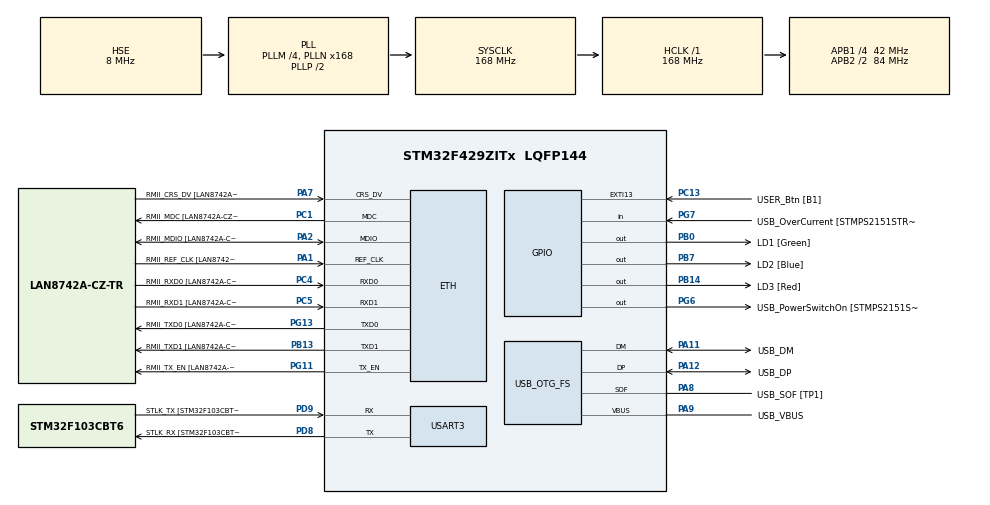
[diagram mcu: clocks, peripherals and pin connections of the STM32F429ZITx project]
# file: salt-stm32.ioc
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ETH.MediaInterface=HAL_ETH_RMII_MODE
ETH.PHY_Name=LAN8742A_PHY_ADDRESS
ETH.PHY_Value=0
ETH.PhyAddress=0
FREERTOS.Tasks01=defaultTask,24,128,StartDefaultTask,Default,NULL,Dynamic,NULL,NULL
Mcu.Family=STM32F4
Mcu.Name=STM32F429ZITx
Mcu.Package=LQFP144
NVIC.PriorityGroup=NVIC_PRIORITYGROUP_4
PA1.GPIO_Label=RMII_REF_CLK [LAN8742A-CZ-TR_REFCLK0]
PA1.Mode=RMII
PA1.Signal=ETH_REF_CLK
PA10.GPIO_Label=USB_ID
PA10.Signal=USB_OTG_FS_ID
PA11.GPIO_Label=USB_DM
PA11.Mode=Device_Only
PA11.Signal=USB_OTG_FS_DM
PA12.GPIO_Label=USB_DP
PA12.Mode=Device_Only
PA12.Signal=USB_OTG_FS_DP
PA13.GPIO_Label=TMS
PA13.Mode=Serial_Wire
PA13.Signal=SYS_JTMS-SWDIO
PA14.GPIO_Label=TCK
PA14.Mode=Serial_Wire
PA14.Signal=SYS_JTCK-SWCLK
PA2.GPIO_Label=RMII_MDIO [LAN8742A-CZ-TR_MDIO]
PA2.Mode=RMII
PA2.Signal=ETH_MDIO
PA7.GPIO_Label=RMII_CRS_DV [LAN8742A-CZ-TR_CRS_DV]
PA7.Mode=RMII
PA7.Signal=ETH_CRS_DV
PA8.GPIO_Label=USB_SOF [TP1]
PA8.Mode=Activate_SOF_FS
PA8.Signal=USB_OTG_FS_SOF
PA9.GPIO_Label=USB_VBUS
PA9.Mode=Activate_VBUS
PA9.Signal=USB_OTG_FS_VBUS
PB0.GPIO_Label=LD1 [Green]
PB0.Signal=GPIO_Output
PB13.GPIO_Label=RMII_TXD1 [LAN8742A-CZ-TR_TXD1]
PB13.Mode=RMII
PB13.Signal=ETH_TXD1
PB14.GPIO_Label=LD3 [Red]
PB14.Signal=GPIO_Output
PB7.GPIO_Label=LD2 [Blue]
PB7.Signal=GPIO_Output
PC1.GPIO_Label=RMII_MDC [LAN8742A-CZ-TR_MDC]
PC1.Mode=RMII
PC1.Signal=ETH_MDC
PC13.GPIO_Label=USER_Btn [B1]
PC13.Signal=GPXTI13
PC14/OSC32_IN.Mode=LSE-External-Oscillator
PC14/OSC32_IN.Signal=RCC_OSC32_IN
PC15/OSC32_OUT.Mode=LSE-External-Oscillator
PC15/OSC32_OUT.Signal=RCC_OSC32_OUT
PC4.GPIO_Label=RMII_RXD0 [LAN8742A-CZ-TR_RXD0]
PC4.Mode=RMII
PC4.Signal=ETH_RXD0
PC5.GPIO_Label=RMII_RXD1 [LAN8742A-CZ-TR_RXD1]
PC5.Mode=RMII
PC5.Signal=ETH_RXD1
PD8.GPIO_Label=STLK_RX [STM32F103CBT6_PA3]
PD8.Mode=Asynchronous
PD8.Signal=USART3_TX
PD9.GPIO_Label=STLK_TX [STM32F103CBT6_PA2]
PD9.Mode=Asynchronous
PD9.Signal=USART3_RX
PG11.GPIO_Label=RMII_TX_EN [LAN8742A-CZ-TR_TXEN]
PG11.Mode=RMII
PG11.Signal=ETH_TX_EN
PG13.GPIO_Label=RMII_TXD0 [LAN8742A-CZ-TR_TXD0]
PG13.Mode=RMII
PG13.Signal=ETH_TXD0
PG6.GPIO_Label=USB_PowerSwitchOn [STMPS2151STR_EN]
PG6.Signal=GPIO_Output
PG7.GPIO_Label=USB_OverCurrent [STMPS2151STR_FAULT]
PG7.Signal=GPIO_Input
PH0/OSC_IN.GPIO_Label=MCO [STM32F103CBT6_PA8]
PH0/OSC_IN.Mode=HSE-External-Clock-Source
PH0/OSC_IN.Signal=RCC_OSC_IN
PH1/OSC_OUT.Mode=HSE-External-Clock-Source
PH1/OSC_OUT.Signal=RCC_OSC_OUT
ProjectManager.HeapSize=0x200
ProjectManager.StackSize=0x400
ProjectManager.TargetToolchain=STM32CubeIDE
RCC.48MHZClocksFreq_Value=48000000
RCC.AHBFreq_Value=168000000
RCC.APB1CLKDivider=RCC_HCLK_DIV4
RCC.APB1Freq_Value=42000000
RCC.APB1TimFreq_Value=84000000
RCC.APB2CLKDivider=RCC_HCLK_DIV2
RCC.APB2Freq_Value=84000000
RCC.APB2TimCLKDivider=2
RCC.APB2TimFreq_Value=168000000
RCC.CortexFreq_Value=168000000
RCC.HCLKFreq_Value=168000000
RCC.HSE_VALUE=8000000
RCC.HSI_VALUE=16000000
RCC.PLLM=4
RCC.PLLMUL=RCC_PLL_MUL9
RCC.PLLN=168
RCC.PLLQ=7
RCC.PRESCALERUSB=RCC_USBCLKSOURCE_PLL_DIV1_5
RCC.SYSCLKFreq_VALUE=168000000
RCC.SYSCLKSource=RCC_SYSCLKSOURCE_PLLCLK
RCC.SYSCLKSourceVirtual=RCC_SYSCLKSOURCE_PLLCLK
RCC.USBFreq_Value=48000000
RCC.VCOOutputFreq_Value=336000000
USART3.VirtualMode=VM_ASYNC
USB_OTG_FS.VirtualMode=Device_Only
VP_FREERTOS_VS_CMSIS_V2.Mode=CMSIS_V2
board=NUCLEO-F429ZI

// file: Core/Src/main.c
/* USER CODE BEGIN Header */
/**
  ******************************************************************************
  * @file           : main.c
  * @brief          : Main program body
  ******************************************************************************
  * @attention
  *
  * Copyright (c) 2022 STMicroelectronics.
  * All rights reserved.
  *
  * This software is licensed under terms that can be found in the LICENSE file
  * in the root directory of this software component.
  * If no LICENSE file comes with this software, it is provided AS-IS.
  *
  ******************************************************************************
  */
/* USER CODE END Header */
#include "main.h"
#include "string.h"
#include "cmsis_os.h"

#include "FreeRTOS.h"

//////////////////////////////////////////////////////////////////////////////////////////////////////////////////////
#include "core_mqtt.h"
#include "backoff_algorithm.h"
#include "using_plaintext.h"
#include "logging_stack.h"

/*-----------------------------------------------------------*/
/* Used by the pseudo random number generator. */
static UBaseType_t ulNextRand;

UBaseType_t uxRand( void )
{
    const uint32_t ulMultiplier = 0x015a4e35UL, ulIncrement = 1UL;

    /*
     * Utility function to generate a pseudo random number.
     *
     * !!!NOTE!!!
     * This is not a secure method of generating a random number.  Production
     * devices should use a True Random Number Generator (TRNG).
     */
    ulNextRand = ( ulMultiplier * ulNextRand ) + ulIncrement;
    return( ( int ) ( ulNextRand >> 16UL ) & 0x7fffUL );
}
/*-----------------------------------------------------------*/

/*
 * Demo for showing use of the managed MQTT API.
 *
 * The Example shown below uses this API to create MQTT messages and
 * send them over the connection established using FreeRTOS sockets.
 * The example is single threaded and uses statically allocated memory;
 * it uses QOS0 and therefore does not implement any retransmission
 * mechanism for Publish messages.
 *
 * !!! NOTE !!!
 * This MQTT demo does not authenticate the server nor the client.
 * Hence, this demo should not be used as production ready code.
 *
 * Also see https://www.freertos.org/mqtt/mqtt-agent-demo.html? for an
 * alternative run time model whereby coreMQTT runs in an autonomous
 * background agent task.  Executing the MQTT protocol in an agent task
 * removes the need for the application writer to explicitly manage any MQTT
 * state or call the MQTT_ProcessLoop() API function. Using an agent task
 * also enables multiple application tasks to more easily share a single
 * MQTT connection.
 */

/* Standard includes. */
#include <string.h>
#include <stdio.h>

/* Kernel includes. */
#include "FreeRTOS.h"
#include "task.h"

/* Demo Specific configs. */
#include "demo_config.h"

/* MQTT library includes. */
#include "core_mqtt.h"

/* Exponential backoff retry include. */
#include "backoff_algorithm.h"

/* Transport interface include. */
#include "using_plaintext.h"

/*-----------------------------------------------------------*/

/* Compile time error for undefined configs. */
#ifndef democonfigMQTT_BROKER_ENDPOINT
#error "Define the config democonfigMQTT_BROKER_ENDPOINT by following the instructions in file demo_config.h."
#endif

/*-----------------------------------------------------------*/

/* Default values for configs. */
#ifndef democonfigCLIENT_IDENTIFIER

/**
 * @brief The MQTT client identifier used in this example.  Each client identifier
 * must be unique so edit as required to ensure no two clients connecting to the
 * same broker use the same client identifier.
 *
 * @note Appending __TIME__ to the client id string will reduce the possibility of a
 * client id collision in the broker. Note that the appended time is the compilation
 * time. This client id can cause collision, if more than one instance of the same
 * binary is used at the same time to connect to the broker.
 */
#define democonfigCLIENT_IDENTIFIER    "testClient"__TIME__
#endif

#ifndef democonfigMQTT_BROKER_PORT

/**
 * @brief The port to use for the demo.
 */
#define democonfigMQTT_BROKER_PORT    ( 1883 )
#endif

/*-----------------------------------------------------------*/

/**
 * @brief The maximum number of retries for network operation with server.
 */
#define mqttexampleRETRY_MAX_ATTEMPTS            ( 5U )

/**
 * @brief The maximum back-off delay (in milliseconds) for retrying failed operation
 *  with server.
 */
#define mqttexampleRETRY_MAX_BACKOFF_DELAY_MS    ( 5000U )

/**
 * @brief The base back-off delay (in milliseconds) to use for network operation retry
 * attempts.
 */
#define mqttexampleRETRY_BACKOFF_BASE_MS         ( 500U )

/**
 * @brief Timeout for receiving CONNACK packet in milliseconds.
 */
#define mqttexampleCONNACK_RECV_TIMEOUT_MS           ( 1000U )

/**
 * @brief The topic to subscribe and publish to in the example.
 *
 * The topic name starts with the client identifier to ensure that each demo
 * interacts with a unique topic name.
 */
#define mqttexampleTOPIC                             democonfigCLIENT_IDENTIFIER "/example/topic"

/**
 * @brief The number of topic filters to subscribe.
 */
#define mqttexampleTOPIC_COUNT                       ( 1 )

/**
 * @brief The MQTT message published in this example.
 */
#define mqttexampleMESSAGE                           "Hello World!"

/**
 * @brief Dimensions a file scope buffer currently used to send and receive MQTT data
 * from a socket.
 */
#define mqttexampleSHARED_BUFFER_SIZE                ( 500U )

/**
 * @brief Time to wait between each cycle of the demo implemented by prvMQTTDemoTask().
 */
#define mqttexampleDELAY_BETWEEN_DEMO_ITERATIONS     ( pdMS_TO_TICKS( 5000U ) )

/**
 * @brief Timeout for MQTT_ProcessLoop in milliseconds.
 */
#define mqttexamplePROCESS_LOOP_TIMEOUT_MS           ( 500U )

/**
 * @brief Keep alive time reported to the broker while establishing an MQTT connection.
 *
 * It is the responsibility of the Client to ensure that the interval between
 * Control Packets being sent does not exceed the this Keep Alive value. In the
 * absence of sending any other Control Packets, the Client MUST send a
 * PINGREQ Packet.
 */
#define mqttexampleKEEP_ALIVE_TIMEOUT_SECONDS        ( 60U )

/**
 * @brief Delay between MQTT publishes. Note that the process loop also has a
 * timeout, so the total time between publishes is the sum of the two delays.
 */
#define mqttexampleDELAY_BETWEEN_PUBLISHES           ( pdMS_TO_TICKS( 500U ) )

/**
 * @brief Transport timeout in milliseconds for transport send and receive.
 */
#define mqttexampleTRANSPORT_SEND_RECV_TIMEOUT_MS    ( 200U )

#define MILLISECONDS_PER_SECOND                      ( 1000U )                                        /**< @brief Milliseconds per second. */
#define MILLISECONDS_PER_TICK                        ( MILLISECONDS_PER_SECOND / configTICK_RATE_HZ ) /**< Milliseconds per FreeRTOS tick. */

/*-----------------------------------------------------------*/

/**
 * @brief Each compilation unit that consumes the NetworkContext must define it.
 * It should contain a single pointer to the type of your desired transport.
 * When using multiple transports in the same compilation unit, define this pointer as void *.
 *
 * @note Transport stacks are defined in FreeRTOS-Plus/Source/Application-Protocols/network_transport.
 */
struct NetworkContext
{
    PlaintextTransportParams_t * pParams;
};

/*-----------------------------------------------------------*/

/**
 * @brief The task used to demonstrate the MQTT API.
 *
 * @param[in] pvParameters Parameters as passed at the time of task creation. Not
 * used in this example.
 */
static void prvMQTTDemoTask( void * pvParameters );

/**
 * @brief Connect to MQTT broker with reconnection retries.
 *
 * If connection fails, retry is attempted after a timeout.
 * Timeout value will exponentially increase until maximum
 * timeout value is reached or the number of attempts are exhausted.
 *
 * @param[out] pxNetworkContext The parameter to return the created network context.
 *
 * @return The status of the final connection attempt.
 */
static PlaintextTransportStatus_t prvConnectToServerWithBackoffRetries( NetworkContext_t * pxNetworkContext );

/**
 * @brief Sends an MQTT Connect packet over the already connected TCP socket.
 *
 * @param[in, out] pxMQTTContext MQTT context pointer.
 * @param[in] pxNetworkContext Network context.
 *
 */
static void prvCreateMQTTConnectionWithBroker( MQTTContext_t * pxMQTTContext,
                                               NetworkContext_t * pxNetworkContext );

/**
 * @brief Function to update variable #xTopicFilterContext with status
 * information from Subscribe ACK. Called by the event callback after processing
 * an incoming SUBACK packet.
 *
 * @param[in] Server response to the subscription request.
 */
static void prvUpdateSubAckStatus( MQTTPacketInfo_t * pxPacketInfo );

/**
 * @brief Subscribes to the topic as specified in mqttexampleTOPIC at the top of
 * this file. In the case of a Subscribe ACK failure, then subscription is
 * retried using an exponential backoff strategy with jitter.
 *
 * @param[in] pxMQTTContext MQTT context pointer.
 */
static void prvMQTTSubscribeWithBackoffRetries( MQTTContext_t * pxMQTTContext );

/**
 * @brief Publishes a message mqttexampleMESSAGE on mqttexampleTOPIC topic.
 *
 * @param[in] pxMQTTContext MQTT context pointer.
 */
static void prvMQTTPublishToTopic( MQTTContext_t * pxMQTTContext );

/**
 * @brief Unsubscribes from the previously subscribed topic as specified
 * in mqttexampleTOPIC.
 *
 * @param[in] pxMQTTContext MQTT context pointer.
 */
static void prvMQTTUnsubscribeFromTopic( MQTTContext_t * pxMQTTContext );

/**
 * @brief The timer query function provided to the MQTT context.
 *
 * @return Time in milliseconds.
 */
static uint32_t prvGetTimeMs( void );

/**
 * @brief Process a response or ack to an MQTT request (PING, SUBSCRIBE
 * or UNSUBSCRIBE). This function processes PINGRESP, SUBACK, and UNSUBACK.
 *
 * @param[in] pxIncomingPacket is a pointer to structure containing deserialized
 * MQTT response.
 * @param[in] usPacketId is the packet identifier from the ack received.
 */
static void prvMQTTProcessResponse( MQTTPacketInfo_t * pxIncomingPacket,
                                    uint16_t usPacketId );

/**
 * @brief Process incoming Publish message.
 *
 * @param[in] pxPublishInfo is a pointer to structure containing deserialized
 * Publish message.
 */
static void prvMQTTProcessIncomingPublish( MQTTPublishInfo_t * pxPublishInfo );

/**
 * @brief The application callback function for getting the incoming publish
 * and incoming acks reported from the MQTT library.
 *
 * @param[in] pxMQTTContext MQTT context pointer.
 * @param[in] pxPacketInfo Packet Info pointer for the incoming packet.
 * @param[in] pxDeserializedInfo Deserialized information from the incoming packet.
 */
static void prvEventCallback( MQTTContext_t * pxMQTTContext,
                              MQTTPacketInfo_t * pxPacketInfo,
                              MQTTDeserializedInfo_t * pxDeserializedInfo );

/*-----------------------------------------------------------*/

/**
 * @brief Static buffer used to hold MQTT messages being sent and received.
 */
static uint8_t ucSharedBuffer[ mqttexampleSHARED_BUFFER_SIZE ];

/**
 * @brief Global entry time into the application to use as a reference timestamp
 * in the #prvGetTimeMs function. #prvGetTimeMs will always return the difference
 * between the current time and the global entry time. This will reduce the chances
 * of overflow for the 32 bit unsigned integer used for holding the timestamp.
 */
static uint32_t ulGlobalEntryTimeMs;

/**
 * @brief Packet Identifier generated when Subscribe request was sent to the broker;
 * it is used to match received Subscribe ACK to the transmitted ACK.
 */
static uint16_t usSubscribePacketIdentifier;

/**
 * @brief Packet Identifier generated when Unsubscribe request was sent to the broker;
 * it is used to match received Unsubscribe response to the transmitted unsubscribe
 * request.
 */
static uint16_t usUnsubscribePacketIdentifier;

/**
 * @brief A pair containing a topic filter and its SUBACK status.
 */
typedef struct topicFilterContext
{
    const char * pcTopicFilter;
    MQTTSubAckStatus_t xSubAckStatus;
} topicFilterContext_t;

/**
 * @brief An array containing the context of a SUBACK; the SUBACK status
 * of a filter is updated when the event callback processes a SUBACK.
 */
static topicFilterContext_t xTopicFilterContext[ mqttexampleTOPIC_COUNT ] =
        {
                { mqttexampleTOPIC, MQTTSubAckFailure }
        };

/**
 * @brief Static buffer used to hold MQTT messages being sent and received.
 */
static MQTTFixedBuffer_t xBuffer =
        {
                .pBuffer = ucSharedBuffer,
                .size    = mqttexampleSHARED_BUFFER_SIZE
        };

/*-----------------------------------------------------------*/

/**
 * @brief Create the task that demonstrates the MQTT API over a plaintext TCP
 * connection.
 */
void vStartSimpleMQTTDemo( void )
{
    /* This example uses a single application task, which in turn is used to
     * connect, subscribe, publish, unsubscribe and disconnect from the MQTT
     * broker.
     *
     * Also see https://www.freertos.org/mqtt/mqtt-agent-demo.html? for an
     * alternative run time model whereby coreMQTT runs in an autonomous
     * background agent task.  Executing the MQTT protocol in an agent task
     * removes the need for the application writer to explicitly manage any MQTT
     * state or call the MQTT_ProcessLoop() API function. Using an agent task
     * also enables multiple application tasks to more easily share a single
     * MQTT connection.*/
    xTaskCreate( prvMQTTDemoTask,          /* Function that implements the task. */
                 "DemoTask",               /* Text name for the task - only used for debugging. */
                 democonfigDEMO_STACKSIZE, /* Size of stack (in words, not bytes) to allocate for the task. */
                 NULL,                     /* Task parameter - not used in this case. */
                 tskIDLE_PRIORITY,         /* Task priority, must be between 0 and configMAX_PRIORITIES - 1. */
                 NULL );                   /* Used to pass out a handle to the created task - not used in this case. */
}
/*-----------------------------------------------------------*/

static void prvMQTTDemoTask( void * pvParameters )
{
    uint32_t ulPublishCount = 0U, ulTopicCount = 0U;
    const uint32_t ulMaxPublishCount = 5UL;
    NetworkContext_t xNetworkContext = { 0 };
    PlaintextTransportParams_t xPlaintextTransportParams = { 0 };
    MQTTContext_t xMQTTContext;
    MQTTStatus_t xMQTTStatus;
    PlaintextTransportStatus_t xNetworkStatus;

    /* Remove compiler warnings about unused parameters. */
    ( void ) pvParameters;

    /* Set the pParams member of the network context with desired transport. */
    xNetworkContext.pParams = &xPlaintextTransportParams;

    ulGlobalEntryTimeMs = prvGetTimeMs();

    for( ; ; )
    {
        /****************************** Connect. ******************************/

        /* Attempt to connect to the MQTT broker. If connection fails, retry after
         * a timeout. The timeout value will exponentially increase until the
         * maximum number of attempts are reached or the maximum timeout value is
         * reached. The function below returns a failure status if the TCP connection
         * cannot be established to the broker after the configured number of attempts. */
        xNetworkStatus = prvConnectToServerWithBackoffRetries( &xNetworkContext );
        configASSERT( xNetworkStatus == PLAINTEXT_TRANSPORT_SUCCESS );

        /* Sends an MQTT Connect packet over the already connected TCP socket,
         * and waits for a connection acknowledgment (CONNACK) packet. */
        LogInfo( ( "Creating an MQTT connection to %s.", democonfigMQTT_BROKER_ENDPOINT ) );
        prvCreateMQTTConnectionWithBroker( &xMQTTContext, &xNetworkContext );

        /**************************** Subscribe. ******************************/

        /* If server rejected the subscription request, attempt to resubscribe to
         * the topic. Attempts are made according to the exponential backoff retry
         * strategy declared in backoff_algorithm.h. */
        prvMQTTSubscribeWithBackoffRetries( &xMQTTContext );

        /******************* Publish and Keep Alive Loop. *********************/
        /* Publish messages with QoS0, then send and process Keep Alive messages. */
        for( ulPublishCount = 0; ulPublishCount < ulMaxPublishCount; ulPublishCount++ )
        {
            LogInfo( ( "Publish to the MQTT topic %s.", mqttexampleTOPIC ) );
            prvMQTTPublishToTopic( &xMQTTContext );

            /* Process the incoming publish echo. Since the application subscribed
             * to the same topic, the broker will send the same publish message
             * back to the application. */
            LogInfo( ( "Attempt to receive publish message from broker." ) );
            //xMQTTStatus = MQTT_ProcessLoop( &xMQTTContext, mqttexamplePROCESS_LOOP_TIMEOUT_MS );
            xMQTTStatus = MQTT_ProcessLoop( &xMQTTContext );
            configASSERT( xMQTTStatus == MQTTSuccess );

            /* Leave the connection idle for some time. */
            LogInfo( ( "Keeping Connection Idle...\r\n" ) );
            vTaskDelay( mqttexampleDELAY_BETWEEN_PUBLISHES );
        }

        /******************** Unsubscribe from the topic. *********************/
        LogInfo( ( "Unsubscribe from the MQTT topic %s.", mqttexampleTOPIC ) );
        prvMQTTUnsubscribeFromTopic( &xMQTTContext );

        /* Process the incoming packet from the broker. */
        //xMQTTStatus = MQTT_ProcessLoop( &xMQTTContext, mqttexamplePROCESS_LOOP_TIMEOUT_MS );
        xMQTTStatus = MQTT_ProcessLoop( &xMQTTContext );
        configASSERT( xMQTTStatus == MQTTSuccess );

        /**************************** Disconnect. *****************************/

        /* Send an MQTT Disconnect packet over the connected TCP socket.
         * There is no corresponding response for a disconnect packet. After
         * sending the disconnect, the client must close the network connection. */
        LogInfo( ( "Disconnecting the MQTT connection with %s.",
                democonfigMQTT_BROKER_ENDPOINT ) );
        xMQTTStatus = MQTT_Disconnect( &xMQTTContext );
        configASSERT( xMQTTStatus == MQTTSuccess );

        /* Close the network connection. */
        xNetworkStatus = Plaintext_FreeRTOS_Disconnect( &xNetworkContext );
        configASSERT( xNetworkStatus == PLAINTEXT_TRANSPORT_SUCCESS );

        /* Reset SUBACK status for each topic filter after completion of
         * subscription request cycle. */
        for( ulTopicCount = 0; ulTopicCount < mqttexampleTOPIC_COUNT; ulTopicCount++ )
        {
            xTopicFilterContext[ ulTopicCount ].xSubAckStatus = MQTTSubAckFailure;
        }

        /* Wait for some time between two iterations to ensure that we do not
         * bombard the MQTT broker. */
        LogInfo( ( "prvMQTTDemoTask() completed an iteration successfully. "
                   "Total free heap is %u.", xPortGetFreeHeapSize() ) );
        LogInfo( ( "Demo completed successfully." ) );
        LogInfo( ( "Short delay before starting the next iteration.... \r\n" ) );
        vTaskDelay( mqttexampleDELAY_BETWEEN_DEMO_ITERATIONS );
    }
}
/*-----------------------------------------------------------*/

static PlaintextTransportStatus_t prvConnectToServerWithBackoffRetries( NetworkContext_t * pxNetworkContext )
{
    PlaintextTransportStatus_t xNetworkStatus;
    BackoffAlgorithmStatus_t xBackoffAlgStatus = BackoffAlgorithmSuccess;
    BackoffAlgorithmContext_t xReconnectParams;
    uint16_t usNextRetryBackOff = 0U;

    /* Initialize reconnect attempts and interval.*/
    BackoffAlgorithm_InitializeParams( &xReconnectParams,
                                       mqttexampleRETRY_BACKOFF_BASE_MS,
                                       mqttexampleRETRY_MAX_BACKOFF_DELAY_MS,
                                       mqttexampleRETRY_MAX_ATTEMPTS );

    /* Attempt to connect to MQTT broker. If connection fails, retry after
     * a timeout. Timeout value will exponentially increase till maximum
     * attempts are reached.
     */
    do
    {
        /* Establish a TCP connection with the MQTT broker. This example connects to
         * the MQTT broker as specified in democonfigMQTT_BROKER_ENDPOINT and
         * democonfigMQTT_BROKER_PORT at the top of this file. */
        LogInfo( ( "Create a TCP connection to %s:%d.",
                democonfigMQTT_BROKER_ENDPOINT,
                democonfigMQTT_BROKER_PORT ) );
        xNetworkStatus = Plaintext_FreeRTOS_Connect( pxNetworkContext,
                                                     democonfigMQTT_BROKER_ENDPOINT,
                                                     democonfigMQTT_BROKER_PORT,
                                                     mqttexampleTRANSPORT_SEND_RECV_TIMEOUT_MS,
                                                     mqttexampleTRANSPORT_SEND_RECV_TIMEOUT_MS );

        if( xNetworkStatus != PLAINTEXT_TRANSPORT_SUCCESS )
        {
            /* Generate a random number and calculate backoff value (in milliseconds) for
             * the next connection retry.
             * Note: It is recommended to seed the random number generator with a device-specific
             * entropy source so that possibility of multiple devices retrying failed network operations
             * at similar intervals can be avoided. */
            xBackoffAlgStatus = BackoffAlgorithm_GetNextBackoff( &xReconnectParams, uxRand(), &usNextRetryBackOff );

            if( xBackoffAlgStatus == BackoffAlgorithmRetriesExhausted )
            {
                FreeRTOS_printf( ( "Connection to the broker failed, all attempts exhausted." ) );
            }
            else if( xBackoffAlgStatus == BackoffAlgorithmSuccess )
            {
                LogWarn( ( "Connection to the broker failed. "
                           "Retrying connection with backoff and jitter." ) );
                vTaskDelay( pdMS_TO_TICKS( usNextRetryBackOff ) );
            }
        }
    } while( ( xNetworkStatus != PLAINTEXT_TRANSPORT_SUCCESS ) && ( xBackoffAlgStatus == BackoffAlgorithmSuccess ) );

    return xNetworkStatus;
}
/*-----------------------------------------------------------*/

static void prvCreateMQTTConnectionWithBroker( MQTTContext_t * pxMQTTContext,
                                               NetworkContext_t * pxNetworkContext )
{
    MQTTStatus_t xResult;
    MQTTConnectInfo_t xConnectInfo;
    bool xSessionPresent;
    TransportInterface_t xTransport;

    /***
     * For readability, error handling in this function is restricted to the use of
     * asserts().
     ***/

    /* Fill in Transport Interface send and receive function pointers. */
    xTransport.pNetworkContext = pxNetworkContext;
    xTransport.send = Plaintext_FreeRTOS_send;
    xTransport.recv = Plaintext_FreeRTOS_recv;

    /* Initialize MQTT library. */
    xResult = MQTT_Init( pxMQTTContext, &xTransport, prvGetTimeMs, prvEventCallback, &xBuffer );
    configASSERT( xResult == MQTTSuccess );

    /* Many fields not used in this demo so start with everything at 0. */
    ( void ) memset( ( void * ) &xConnectInfo, 0x00, sizeof( xConnectInfo ) );

    /* Start with a clean session i.e. direct the MQTT broker to discard any
     * previous session data. Also, establishing a connection with clean session
     * will ensure that the broker does not store any data when this client
     * gets disconnected. */
    xConnectInfo.cleanSession = true;

    /* The client identifier is used to uniquely identify this MQTT client to
     * the MQTT broker. In a production device the identifier can be something
     * unique, such as a device serial number. */
    xConnectInfo.pClientIdentifier = democonfigCLIENT_IDENTIFIER;
    xConnectInfo.clientIdentifierLength = ( uint16_t ) strlen( democonfigCLIENT_IDENTIFIER );

    /* Set MQTT keep-alive period. It is the responsibility of the application to ensure
     * that the interval between Control Packets being sent does not exceed the Keep Alive value.
     * In the absence of sending any other Control Packets, the Client MUST send a PINGREQ Packet. */
    xConnectInfo.keepAliveSeconds = mqttexampleKEEP_ALIVE_TIMEOUT_SECONDS;

    /* Send MQTT CONNECT packet to broker. LWT is not used in this demo, so it
     * is passed as NULL. */
    xResult = MQTT_Connect( pxMQTTContext,
                            &xConnectInfo,
                            NULL,
                            mqttexampleCONNACK_RECV_TIMEOUT_MS,
                            &xSessionPresent );
    configASSERT( xResult == MQTTSuccess );
}
/*-----------------------------------------------------------*/

static void prvUpdateSubAckStatus( MQTTPacketInfo_t * pxPacketInfo )
{
    MQTTStatus_t xResult = MQTTSuccess;
    uint8_t * pucPayload = NULL;
    size_t ulSize = 0;
    uint32_t ulTopicCount = 0U;

    xResult = MQTT_GetSubAckStatusCodes( pxPacketInfo, &pucPayload, &ulSize );

    /* MQTT_GetSubAckStatusCodes always returns success if called with packet info
     * from the event callback and non-NULL parameters. */
    configASSERT( xResult == MQTTSuccess );

    for( ulTopicCount = 0; ulTopicCount < ulSize; ulTopicCount++ )
    {
        xTopicFilterContext[ ulTopicCount ].xSubAckStatus = pucPayload[ ulTopicCount ];
    }
}
/*-----------------------------------------------------------*/

static void prvMQTTSubscribeWithBackoffRetries( MQTTContext_t * pxMQTTContext )
{
    MQTTStatus_t xResult = MQTTSuccess;
    BackoffAlgorithmStatus_t xBackoffAlgStatus = BackoffAlgorithmSuccess;
    BackoffAlgorithmContext_t xRetryParams;
    uint16_t usNextRetryBackOff = 0U;
    MQTTSubscribeInfo_t xMQTTSubscription[ mqttexampleTOPIC_COUNT ];
    bool xFailedSubscribeToTopic = false;
    uint32_t ulTopicCount = 0U;

    /* Some fields not used by this demo so start with everything at 0. */
    ( void ) memset( ( void * ) &xMQTTSubscription, 0x00, sizeof( xMQTTSubscription ) );

    /* Get a unique packet id. */
    usSubscribePacketIdentifier = MQTT_GetPacketId( pxMQTTContext );

    /* Subscribe to the mqttexampleTOPIC topic filter. This example subscribes to
     * only one topic and uses QoS0. */
    xMQTTSubscription[ 0 ].qos = MQTTQoS0;
    xMQTTSubscription[ 0 ].pTopicFilter = mqttexampleTOPIC;
    xMQTTSubscription[ 0 ].topicFilterLength = ( uint16_t ) strlen( mqttexampleTOPIC );

    /* Initialize context for backoff retry attempts if SUBSCRIBE request fails. */
    BackoffAlgorithm_InitializeParams( &xRetryParams,
                                       mqttexampleRETRY_BACKOFF_BASE_MS,
                                       mqttexampleRETRY_MAX_BACKOFF_DELAY_MS,
                                       mqttexampleRETRY_MAX_ATTEMPTS );

    do
    {
        /* The client is now connected to the broker. Subscribe to the topic
         * as specified in mqttexampleTOPIC at the top of this file by sending a
         * subscribe packet then waiting for a subscribe acknowledgment (SUBACK).
         * This client will then publish to the same topic it subscribed to, so it
         * will expect all the messages it sends to the broker to be sent back to it
         * from the broker. This demo uses QOS0 in Subscribe, therefore, the Publish
         * messages received from the broker will have QOS0. */
        LogInfo( ( "Attempt to subscribe to the MQTT topic %s.", mqttexampleTOPIC ) );
        xResult = MQTT_Subscribe( pxMQTTContext,
                                  xMQTTSubscription,
                                  sizeof( xMQTTSubscription ) / sizeof( MQTTSubscribeInfo_t ),
                                  usSubscribePacketIdentifier );
        configASSERT( xResult == MQTTSuccess );

        LogInfo( ( "SUBSCRIBE sent for topic %s to broker.\n\n", mqttexampleTOPIC ) );

        /* Process incoming packet from the broker. After sending the subscribe, the
         * client may receive a publish before it receives a subscribe ack. Therefore,
         * call generic incoming packet processing function. Since this demo is
         * subscribing to the topic to which no one is publishing, probability of
         * receiving Publish message before subscribe ack is zero; but application
         * must be ready to receive any packet.  This demo uses the generic packet
         * processing function everywhere to highlight this fact. */
        //xResult = MQTT_ProcessLoop( pxMQTTContext, mqttexamplePROCESS_LOOP_TIMEOUT_MS );
        xResult = MQTT_ProcessLoop( pxMQTTContext );
        configASSERT( xResult == MQTTSuccess );

        /* Reset flag before checking suback responses. */
        xFailedSubscribeToTopic = false;

        /* Check if recent subscription request has been rejected. #xTopicFilterContext is updated
         * in the event callback to reflect the status of the SUBACK sent by the broker. It represents
         * either the QoS level granted by the server upon subscription, or acknowledgement of
         * server rejection of the subscription request. */
        for( ulTopicCount = 0; ulTopicCount < mqttexampleTOPIC_COUNT; ulTopicCount++ )
        {
            if( xTopicFilterContext[ ulTopicCount ].xSubAckStatus == MQTTSubAckFailure )
            {
                xFailedSubscribeToTopic = true;

                /* Generate a random number and calculate backoff value (in milliseconds) for
                 * the next connection retry.
                 * Note: It is recommended to seed the random number generator with a device-specific
                 * entropy source so that possibility of multiple devices retrying failed network operations
                 * at similar intervals can be avoided. */
                xBackoffAlgStatus = BackoffAlgorithm_GetNextBackoff( &xRetryParams, uxRand(), &usNextRetryBackOff );

                if( xBackoffAlgStatus == BackoffAlgorithmRetriesExhausted )
                {
                    FreeRTOS_printf( ( "Server rejected subscription request. All retry attempts have exhausted. Topic=%s",
                            xTopicFilterContext[ ulTopicCount ].pcTopicFilter ) );
                }
                else if( xBackoffAlgStatus == BackoffAlgorithmSuccess )
                {
                    LogWarn( ( "Server rejected subscription request. Attempting to re-subscribe to topic %s.",
                            xTopicFilterContext[ ulTopicCount ].pcTopicFilter ) );
                    /* Backoff before the next re-subscribe attempt. */
                    vTaskDelay( pdMS_TO_TICKS( usNextRetryBackOff ) );
                }

                break;
            }
        }

        configASSERT( xBackoffAlgStatus != BackoffAlgorithmRetriesExhausted );
    } while( ( xFailedSubscribeToTopic == true ) && ( xBackoffAlgStatus == BackoffAlgorithmSuccess ) );
}
/*-----------------------------------------------------------*/

static void prvMQTTPublishToTopic( MQTTContext_t * pxMQTTContext )
{
    MQTTStatus_t xResult;
    MQTTPublishInfo_t xMQTTPublishInfo;

    /***
     * For readability, error handling in this function is restricted to the use of
     * asserts().
     ***/

    /* Some fields are not used by this demo so start with everything at 0. */
    ( void ) memset( ( void * ) &xMQTTPublishInfo, 0x00, sizeof( xMQTTPublishInfo ) );

    /* This demo uses QoS0. */
    xMQTTPublishInfo.qos = MQTTQoS0;
    xMQTTPublishInfo.retain = false;
    xMQTTPublishInfo.pTopicName = mqttexampleTOPIC;
    xMQTTPublishInfo.topicNameLength = ( uint16_t ) strlen( mqttexampleTOPIC );
    xMQTTPublishInfo.pPayload = mqttexampleMESSAGE;
    xMQTTPublishInfo.payloadLength = strlen( mqttexampleMESSAGE );

    /* Send PUBLISH packet. Packet ID is not used for a QoS0 publish. */
    xResult = MQTT_Publish( pxMQTTContext, &xMQTTPublishInfo, 0U );

    configASSERT( xResult == MQTTSuccess );
}
/*-----------------------------------------------------------*/

static void prvMQTTUnsubscribeFromTopic( MQTTContext_t * pxMQTTContext )
{
    MQTTStatus_t xResult;
    MQTTSubscribeInfo_t xMQTTSubscription[ mqttexampleTOPIC_COUNT ];

    /* Some fields not used by this demo so start with everything at 0. */
    ( void ) memset( ( void * ) &xMQTTSubscription, 0x00, sizeof( xMQTTSubscription ) );

    /* Get a unique packet id. */
    usSubscribePacketIdentifier = MQTT_GetPacketId( pxMQTTContext );

    /* Subscribe to the mqttexampleTOPIC topic filter. This example subscribes to
     * only one topic and uses QoS0. */
    xMQTTSubscription[ 0 ].qos = MQTTQoS0;
    xMQTTSubscription[ 0 ].pTopicFilter = mqttexampleTOPIC;
    xMQTTSubscription[ 0 ].topicFilterLength = ( uint16_t ) strlen( mqttexampleTOPIC );

    /* Get next unique packet identifier. */
    usUnsubscribePacketIdentifier = MQTT_GetPacketId( pxMQTTContext );

    /* Send UNSUBSCRIBE packet. */
    xResult = MQTT_Unsubscribe( pxMQTTContext,
                                xMQTTSubscription,
                                sizeof( xMQTTSubscription ) / sizeof( MQTTSubscribeInfo_t ),
                                usUnsubscribePacketIdentifier );

    configASSERT( xResult == MQTTSuccess );
}
/*-----------------------------------------------------------*/

static void prvMQTTProcessResponse( MQTTPacketInfo_t * pxIncomingPacket,
                                    uint16_t usPacketId )
{
    uint32_t ulTopicCount = 0U;

    switch( pxIncomingPacket->type )
    {
        case MQTT_PACKET_TYPE_SUBACK:

            /* A SUBACK from the broker, containing the server response to our subscription request, has been received.
             * It contains the status code indicating server approval/rejection for the subscription to the single topic
             * requested. The SUBACK will be parsed to obtain the status code, and this status code will be stored in global
             * variable #xTopicFilterContext. */
            prvUpdateSubAckStatus( pxIncomingPacket );

            for( ulTopicCount = 0; ulTopicCount < mqttexampleTOPIC_COUNT; ulTopicCount++ )
            {
                if( xTopicFilterContext[ ulTopicCount ].xSubAckStatus != MQTTSubAckFailure )
                {
                    LogInfo( ( "Subscribed to the topic %s with maximum QoS %u.",
                            xTopicFilterContext[ ulTopicCount ].pcTopicFilter,
                            xTopicFilterContext[ ulTopicCount ].xSubAckStatus ) );
                }
            }

            /* Make sure ACK packet identifier matches with Request packet identifier. */
            configASSERT( usSubscribePacketIdentifier == usPacketId );
            break;

        case MQTT_PACKET_TYPE_UNSUBACK:
        LogInfo( ( "Unsubscribed from the topic %s.", mqttexampleTOPIC ) );
            /* Make sure ACK packet identifier matches with Request packet identifier. */
            configASSERT( usUnsubscribePacketIdentifier == usPacketId );
            break;

        case MQTT_PACKET_TYPE_PINGRESP:

            /* Nothing to be done from application as library handles
             * PINGRESP with the use of MQTT_ProcessLoop API function. */
        LogWarn( ( "PINGRESP should not be handled by the application "
                   "callback when using MQTT_ProcessLoop.\n" ) );
            break;

            /* Any other packet type is invalid. */
        default:
        LogWarn( ( "prvMQTTProcessResponse() called with unknown packet type:(%02X).",
                pxIncomingPacket->type ) );
    }
}

/*-----------------------------------------------------------*/

static void prvMQTTProcessIncomingPublish( MQTTPublishInfo_t * pxPublishInfo )
{
    configASSERT( pxPublishInfo != NULL );

    /* Process incoming Publish. */
    LogInfo( ( "Incoming QoS : %d\n", pxPublishInfo->qos ) );

    /* Verify the received publish is for the we have subscribed to. */
    if( ( pxPublishInfo->topicNameLength == strlen( mqttexampleTOPIC ) ) &&
        ( 0 == strncmp( mqttexampleTOPIC, pxPublishInfo->pTopicName, pxPublishInfo->topicNameLength ) ) )
    {
        LogInfo( ( "Incoming Publish Topic Name: %.*s matches subscribed topic.\r\n"
                   "Incoming Publish Message : %.*s",
                pxPublishInfo->topicNameLength,
                pxPublishInfo->pTopicName,
                pxPublishInfo->payloadLength,
                pxPublishInfo->pPayload ) );
    }
    else
    {
        LogInfo( ( "Incoming Publish Topic Name: %.*s does not match subscribed topic.",
                pxPublishInfo->topicNameLength,
                pxPublishInfo->pTopicName ) );
    }
}

/*-----------------------------------------------------------*/

static void prvEventCallback( MQTTContext_t * pxMQTTContext,
                              MQTTPacketInfo_t * pxPacketInfo,
                              MQTTDeserializedInfo_t * pxDeserializedInfo )
{
    /* The MQTT context is not used for this demo. */
    ( void ) pxMQTTContext;

    if( ( pxPacketInfo->type & 0xF0U ) == MQTT_PACKET_TYPE_PUBLISH )
    {
        prvMQTTProcessIncomingPublish( pxDeserializedInfo->pPublishInfo );
    }
    else
    {
        prvMQTTProcessResponse( pxPacketInfo, pxDeserializedInfo->packetIdentifier );
    }
}

/*-----------------------------------------------------------*/

static uint32_t prvGetTimeMs( void )
{
    TickType_t xTickCount = 0;
    uint32_t ulTimeMs = 0UL;

    /* Get the current tick count. */
    xTickCount = xTaskGetTickCount();

    /* Convert the ticks to milliseconds. */
    ulTimeMs = ( uint32_t ) xTickCount * MILLISECONDS_PER_TICK;

    /* Reduce ulGlobalEntryTimeMs from obtained time so as to always return the
     * elapsed time in the application. */
    ulTimeMs = ( uint32_t ) ( ulTimeMs - ulGlobalEntryTimeMs );

    return ulTimeMs;
}

/*-----------------------------------------------------------*/

ETH_TxPacketConfig TxConfig;
ETH_DMADescTypeDef  DMARxDscrTab[ETH_RX_DESC_CNT]; /* Ethernet Rx DMA Descriptors */
ETH_DMADescTypeDef  DMATxDscrTab[ETH_TX_DESC_CNT]; /* Ethernet Tx DMA Descriptors */

ETH_HandleTypeDef heth;

UART_HandleTypeDef huart3;

PCD_HandleTypeDef hpcd_USB_OTG_FS;

/* Definitions for defaultTask */
osThreadId_t defaultTaskHandle;
const osThreadAttr_t defaultTask_attributes = {
  .name = "defaultTask",
  .stack_size = 128 * 4,
  .priority = (osPriority_t) osPriorityNormal,
};

void SystemClock_Config(void);
static void MX_GPIO_Init(void);
static void MX_ETH_Init(void);
static void MX_USART3_UART_Init(void);
static void MX_USB_OTG_FS_PCD_Init(void);
void StartDefaultTask(void *argument);

int main(void)
{

  /* MCU Configuration--------------------------------------------------------*/

  /* Reset of all peripherals, Initializes the Flash interface and the Systick. */
  HAL_Init();

  /* Configure the system clock */
  SystemClock_Config();

  /* Initialize all configured peripherals */
  MX_GPIO_Init();
  MX_ETH_Init();
  MX_USART3_UART_Init();
  MX_USB_OTG_FS_PCD_Init();

  /* Init scheduler */
  osKernelInitialize();

  /* Create the thread(s) */
  /* creation of defaultTask */
  defaultTaskHandle = osThreadNew(StartDefaultTask, NULL, &defaultTask_attributes);

  /* Start scheduler */
  osKernelStart();

  /* We should never get here as control is now taken by the scheduler */
  /* Infinite loop */
  /* USER CODE BEGIN WHILE */
  while (1)
  {

      printf("HALO !");

      vStartSimpleMQTTDemo();

    /* USER CODE END WHILE */

  }
}

void SystemClock_Config(void)
{
  RCC_OscInitTypeDef RCC_OscInitStruct = {0};
  RCC_ClkInitTypeDef RCC_ClkInitStruct = {0};

  /** Configure the main internal regulator output voltage
  */
  __HAL_RCC_PWR_CLK_ENABLE();
  __HAL_PWR_VOLTAGESCALING_CONFIG(PWR_REGULATOR_VOLTAGE_SCALE1);

  /** Initializes the RCC Oscillators according to the specified parameters
  * in the RCC_OscInitTypeDef structure.
  */
  RCC_OscInitStruct.OscillatorType = RCC_OSCILLATORTYPE_HSE;
  RCC_OscInitStruct.HSEState = RCC_HSE_BYPASS;
  RCC_OscInitStruct.PLL.PLLState = RCC_PLL_ON;
  RCC_OscInitStruct.PLL.PLLSource = RCC_PLLSOURCE_HSE;
  RCC_OscInitStruct.PLL.PLLM = 4;
  RCC_OscInitStruct.PLL.PLLN = 168;
  RCC_OscInitStruct.PLL.PLLP = RCC_PLLP_DIV2;
  RCC_OscInitStruct.PLL.PLLQ = 7;
  if (HAL_RCC_OscConfig(&RCC_OscInitStruct) != HAL_OK)
  {
    Error_Handler();
  }

  /** Initializes the CPU, AHB and APB buses clocks
  */
  RCC_ClkInitStruct.ClockType = RCC_CLOCKTYPE_HCLK|RCC_CLOCKTYPE_SYSCLK
                              |RCC_CLOCKTYPE_PCLK1|RCC_CLOCKTYPE_PCLK2;
  RCC_ClkInitStruct.SYSCLKSource = RCC_SYSCLKSOURCE_PLLCLK;
  RCC_ClkInitStruct.AHBCLKDivider = RCC_SYSCLK_DIV1;
  RCC_ClkInitStruct.APB1CLKDivider = RCC_HCLK_DIV4;
  RCC_ClkInitStruct.APB2CLKDivider = RCC_HCLK_DIV2;

  if (HAL_RCC_ClockConfig(&RCC_ClkInitStruct, FLASH_LATENCY_5) != HAL_OK)
  {
    Error_Handler();
  }
}

static void MX_ETH_Init(void)
{

   static uint8_t MACAddr[6];

  heth.Instance = ETH;
  MACAddr[0] = 0x00;
  MACAddr[1] = 0x80;
  MACAddr[2] = 0xE1;
  MACAddr[3] = 0x00;
  MACAddr[4] = 0x00;
  MACAddr[5] = 0x00;
  heth.Init.MACAddr = &MACAddr[0];
  heth.Init.MediaInterface = HAL_ETH_RMII_MODE;
  heth.Init.TxDesc = DMATxDscrTab;
  heth.Init.RxDesc = DMARxDscrTab;
  heth.Init.RxBuffLen = 1524;

  if (HAL_ETH_Init(&heth) != HAL_OK)
  {
    Error_Handler();
  }

  memset(&TxConfig, 0 , sizeof(ETH_TxPacketConfig));
  TxConfig.Attributes = ETH_TX_PACKETS_FEATURES_CSUM | ETH_TX_PACKETS_FEATURES_CRCPAD;
  TxConfig.ChecksumCtrl = ETH_CHECKSUM_IPHDR_PAYLOAD_INSERT_PHDR_CALC;
  TxConfig.CRCPadCtrl = ETH_CRC_PAD_INSERT;

}

static void MX_USART3_UART_Init(void)
{

  huart3.Instance = USART3;
  huart3.Init.BaudRate = 115200;
  huart3.Init.WordLength = UART_WORDLENGTH_8B;
  huart3.Init.StopBits = UART_STOPBITS_1;
  huart3.Init.Parity = UART_PARITY_NONE;
  huart3.Init.Mode = UART_MODE_TX_RX;
  huart3.Init.HwFlowCtl = UART_HWCONTROL_NONE;
  huart3.Init.OverSampling = UART_OVERSAMPLING_16;
  if (HAL_UART_Init(&huart3) != HAL_OK)
  {
    Error_Handler();
  }

}

static void MX_USB_OTG_FS_PCD_Init(void)
{

  hpcd_USB_OTG_FS.Instance = USB_OTG_FS;
  hpcd_USB_OTG_FS.Init.dev_endpoints = 4;
  hpcd_USB_OTG_FS.Init.speed = PCD_SPEED_FULL;
  hpcd_USB_OTG_FS.Init.dma_enable = DISABLE;
  hpcd_USB_OTG_FS.Init.phy_itface = PCD_PHY_EMBEDDED;
  hpcd_USB_OTG_FS.Init.Sof_enable = ENABLE;
  hpcd_USB_OTG_FS.Init.low_power_enable = DISABLE;
  hpcd_USB_OTG_FS.Init.lpm_enable = DISABLE;
  hpcd_USB_OTG_FS.Init.vbus_sensing_enable = ENABLE;
  hpcd_USB_OTG_FS.Init.use_dedicated_ep1 = DISABLE;
  if (HAL_PCD_Init(&hpcd_USB_OTG_FS) != HAL_OK)
  {
    Error_Handler();
  }

}

static void MX_GPIO_Init(void)
{
  GPIO_InitTypeDef GPIO_InitStruct = {0};

  /* GPIO Ports Clock Enable */
  __HAL_RCC_GPIOC_CLK_ENABLE();
  __HAL_RCC_GPIOH_CLK_ENABLE();
  __HAL_RCC_GPIOA_CLK_ENABLE();
  __HAL_RCC_GPIOB_CLK_ENABLE();
  __HAL_RCC_GPIOD_CLK_ENABLE();
  __HAL_RCC_GPIOG_CLK_ENABLE();

  /*Configure GPIO pin Output Level */
  HAL_GPIO_WritePin(GPIOB, LD1_Pin|LD3_Pin|LD2_Pin, GPIO_PIN_RESET);

  /*Configure GPIO pin Output Level */
  HAL_GPIO_WritePin(USB_PowerSwitchOn_GPIO_Port, USB_PowerSwitchOn_Pin, GPIO_PIN_RESET);

  /*Configure GPIO pin : USER_Btn_Pin */
  GPIO_InitStruct.Pin = USER_Btn_Pin;
  GPIO_InitStruct.Mode = GPIO_MODE_IT_RISING;
  GPIO_InitStruct.Pull = GPIO_NOPULL;
  HAL_GPIO_Init(USER_Btn_GPIO_Port, &GPIO_InitStruct);

  /*Configure GPIO pins : LD1_Pin LD3_Pin LD2_Pin */
  GPIO_InitStruct.Pin = LD1_Pin|LD3_Pin|LD2_Pin;
  GPIO_InitStruct.Mode = GPIO_MODE_OUTPUT_PP;
  GPIO_InitStruct.Pull = GPIO_NOPULL;
  GPIO_InitStruct.Speed = GPIO_SPEED_FREQ_LOW;
  HAL_GPIO_Init(GPIOB, &GPIO_InitStruct);

  /*Configure GPIO pin : USB_PowerSwitchOn_Pin */
  GPIO_InitStruct.Pin = USB_PowerSwitchOn_Pin;
  GPIO_InitStruct.Mode = GPIO_MODE_OUTPUT_PP;
  GPIO_InitStruct.Pull = GPIO_NOPULL;
  GPIO_InitStruct.Speed = GPIO_SPEED_FREQ_LOW;
  HAL_GPIO_Init(USB_PowerSwitchOn_GPIO_Port, &GPIO_InitStruct);

  /*Configure GPIO pin : USB_OverCurrent_Pin */
  GPIO_InitStruct.Pin = USB_OverCurrent_Pin;
  GPIO_InitStruct.Mode = GPIO_MODE_INPUT;
  GPIO_InitStruct.Pull = GPIO_NOPULL;
  HAL_GPIO_Init(USB_OverCurrent_GPIO_Port, &GPIO_InitStruct);

}

void StartDefaultTask(void *argument)
{
  for(;;)
  {
    osDelay(1);
  }
}

void Error_Handler(void)
{
  __disable_irq();
  while (1)
  {
  }
}
